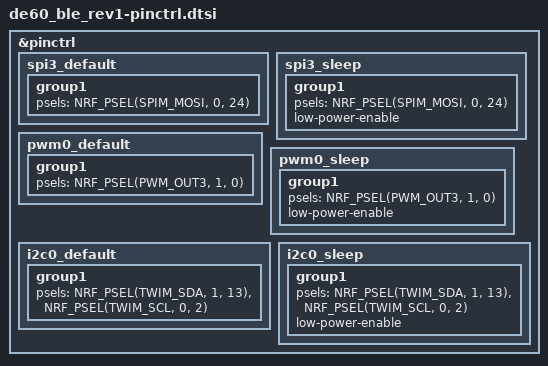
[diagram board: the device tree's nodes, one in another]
/*
 * Copyright (c) 2022 The ZMK Contributors
 * SPDX-License-Identifier: MIT
 */


&pinctrl {
    spi3_default: spi3_default {
        group1 {
            psels = <NRF_PSEL(SPIM_MOSI, 0, 24)>;  // P0.24 Underglow
        };
    };
    
    spi3_sleep: spi3_sleep {
        group1 {
            psels = <NRF_PSEL(SPIM_MOSI, 0, 24)>;
            low-power-enable;
        };
    };

    pwm0_default: pwm0_default {
        group1 {
            psels = <NRF_PSEL(PWM_OUT3, 1, 0)>;  // P1.00 Buzzer
        };
    };

    pwm0_sleep: pwm0_sleep {
        group1 {
            psels = <NRF_PSEL(PWM_OUT3, 1, 0)>;
            low-power-enable;
        };
    };

    i2c0_default: i2c0_default {
        group1 {
            psels = <NRF_PSEL(TWIM_SDA, 1, 13)>,  // P0.13 SDA
                    <NRF_PSEL(TWIM_SCL, 0,  2)>;  // P0.02 SCL
        };
    };

    i2c0_sleep: i2c0_sleep {
        group1 {
            psels = <NRF_PSEL(TWIM_SDA, 1, 13)>,
                    <NRF_PSEL(TWIM_SCL, 0,  2)>;
            low-power-enable;
        };
    };
};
